# dp_source_model: IP-XACT component
VLNV IcronTechnologies:IcronTechnologies:dp_source_model:1.0

## Parameters
addr_width = 9
bus_width = 32

## Bus interfaces (logical=physical port)
default_map: slave AGNISYS:AGNISYS:APB:1.0, memory map dp_sourcemap
  pclk=pclk, presetn=presetn, psel=psel, penable=penable, pwrite=pwrite, pprot=pprot, pstrb=pstrb, pwdata=pwdata, paddr=paddr, pready=pready, prdata=prdata, pslverr=pslverr

## Ports
in pclk
in presetn
in psel
in penable
in pwrite
in pprot[2:0]
in pstrb[(bus_width div 8 )-1:0]
in pwdata[bus_width -1:0]
in paddr[addr_width -1:0]
out pready
out prdata[bus_width -1:0]
out pslverr
out dp_source_regsversion_major_r[7:0]
out dp_source_regsversion_minor_r[7:0]
out dp_source_regsversion_patch_r[7:0]
out dp_source_regsconfiguration_enb
out dp_source_regsconfiguration_debug_sel_r[3:0]
out dp_source_regsconfiguration_dp_training_done_r
out dp_source_regsconfiguration_vid_stream_end_r
out dp_source_regsconfiguration_apb_to_axi_mode_select_r
out dp_source_regsconfiguration_pix_gen_mode_r[1:0]
out dp_source_regsconfiguration_pix_gen_sel_r
out dp_source_regsconfiguration_dp_enh_frm_en_r
out dp_source_regsconfiguration_decoder_error_inject_r
out dp_source_regsconfiguration_vid_stream_generator_en_r
out dp_source_regsconfiguration_syn_stream_generator_en_r
out dp_source_regsconfiguration_sdp_en_r
out dp_source_regsconfiguration_lane_bit_rate_r[1:0]
out dp_source_regsconfiguration_tps_sel_r[3:0]
out dp_source_regsconfiguration_lane_num_r[1:0]
out dp_source_regsscrambler_enb
out dp_source_regsscrambler_enable_r
out dp_source_regsstream_generator_cfg{n}_enb (n=0..3)
out dp_source_regsstream_generator_cfg0_cs_start_level_r[11:0]
out dp_source_regsstream_generator_cfg0_cs_pkt_length_r[9:0]
out dp_source_regsstream_generator_cfg0_pix_start_level_r[9:0]
out dp_source_regsstream_generator_cfg1_cs_fifo_level_check_frequency_r[9:0]
out dp_source_regsstream_generator_cfg1_cs_pkt_interval_r[12:0]
out dp_source_regsstream_generator_cfg2_cs_pkt_interval_feedback_ctrl_r
out dp_source_regsstream_generator_cfg2_cs_pkt_interval_feedback_ctrl_debug_r[3:0]
out dp_source_regsstream_generator_cfg2_cs_pkt_interval_minus_offset0_r[3:0]
out dp_source_regsstream_generator_cfg2_cs_pkt_interval_plus_offset0_r[3:0]
out dp_source_regsstream_generator_cfg3_dp_width_total_feedback_ctrl_r
out dp_source_regsstream_generator_cfg3_dp_width_total_feedback_ctrl_debug_r[3:0]
out dp_source_regsstream_generator_cfg3_dp_width_total_minus_offset1_r[3:0]
out dp_source_regsstream_generator_cfg3_dp_width_total_plus_offset1_r[3:0]
out dp_source_regsstream_generator_cfg3_dp_width_total_minus_offset0_r[3:0]
out dp_source_regsstream_generator_cfg3_dp_width_total_plus_offset0_r[3:0]
out dp_source_regsstream_generator_alu{n}_enb (n=0..2)
out dp_source_regsstream_generator_alu0_dp_width_active_r[14:0]
out dp_source_regsstream_generator_alu0_dp_width_total_r[14:0]
out dp_source_regsstream_generator_alu1_full_tu_size_r[6:0]
out dp_source_regsstream_generator_alu1_last_tu_size_r[6:0]
out dp_source_regsstream_generator_alu1_full_tu_num_r[8:0]
out dp_source_regsstream_generator_alu2_cpu_math_result_rdy_r
out dp_source_regsstream_generator_alu2_valid_bytes_repeat_num_r[8:0]
out dp_source_regsstream_generator_alu2_valid_bytes_per_full_tu_r[6:0]
out dp_source_regsstream_generator_alu2_valid_bytes_num_per_lane_r[14:0]
out dp_source_regsstream_generator_fifo_cs_control0_enb
out dp_source_regsstream_generator_fifo_cs_control0_aet0_r[15:0]
out dp_source_regsstream_generator_fifo_cs_control0_aft0_r[15:0]
out dp_source_regsstream_generator_fifo_cs_control1_enb
out dp_source_regsstream_generator_fifo_cs_control1_aet1_r[15:0]
out dp_source_regsstream_generator_fifo_cs_control1_aft1_r[15:0]
out dp_source_regsstream_generator_fifo_pix_control{n}_enb (n=0..2)
out dp_source_regsstream_generator_fifo_pix_control0_aet0_r[15:0]
out dp_source_regsstream_generator_fifo_pix_control0_aft0_r[15:0]
out dp_source_regsstream_generator_fifo_pix_control1_aet1_r[15:0]
out dp_source_regsstream_generator_fifo_pix_control1_aft1_r[15:0]
out dp_source_regsstream_generator_fifo_pix_control2_offset_r[15:0]
out dp_source_regsstream_generator_sdp_ctrl_enb
out dp_source_regsstream_generator_sdp_ctrl_maud_set_value_r[7:0]
out dp_source_regsstream_generator_sdp_ctrl_maud_method_sel_r
out dp_source_regsstream_generator_sdp_ctrl_audiomute_flag_r
out dp_source_regsstream_generator_idle_pattern_debug_enb
out dp_source_regsstream_generator_idle_pattern_debug_cnt_rst_r
out dp_source_regsstream_generator_msa_control_0_enb
out dp_source_regsstream_generator_msa_control_0_nvid_sel_r
out dp_source_regsstream_generator_msa_control_0_mvid_sel_r[1:0]
out dp_source_regsstream_generator_msa_control_0_mvid_set_value_r[23:0]
out dp_source_regsstream_generator_msa_control_1_enb
out dp_source_regsstream_generator_msa_control_1_insert_line_sel_r[7:0]
out dp_source_regsstream_generator_msa_control_1_nvid_set_value_r[23:0]
out dp_source_regsstream_generator_msa_mvid_enb
out dp_source_regsstream_generator_msa_mvid_mvid_r[23:0]
out dp_source_regsstream_generator_msa_nvid_enb
out dp_source_regsstream_generator_msa_nvid_nvid_r[23:0]
out dp_source_regsstream_generator_msa_horizontal_0_enb
out dp_source_regsstream_generator_msa_horizontal_0_total_r[15:0]
out dp_source_regsstream_generator_msa_horizontal_0_start_r[15:0]
out dp_source_regsstream_generator_msa_horizontal_1_enb
out dp_source_regsstream_generator_msa_horizontal_1_width_r[15:0]
out dp_source_regsstream_generator_msa_horizontal_1_polarity_r
out dp_source_regsstream_generator_msa_horizontal_1_sync_width_r[14:0]
out dp_source_regsstream_generator_msa_vertical_0_enb
out dp_source_regsstream_generator_msa_vertical_0_total_r[15:0]
out dp_source_regsstream_generator_msa_vertical_0_start_r[15:0]
out dp_source_regsstream_generator_msa_vertical_1_enb
out dp_source_regsstream_generator_msa_vertical_1_height_r[15:0]
out dp_source_regsstream_generator_msa_vertical_1_polarity_r
out dp_source_regsstream_generator_msa_vertical_1_sync_width_r[14:0]
out dp_source_regsstream_generator_msa_misc_enb
out dp_source_regsstream_generator_msa_misc_reserved_r[2:0]
out dp_source_regsstream_generator_msa_misc_vsc_sdp_r
out dp_source_regsstream_generator_msa_misc_y_only_r
out dp_source_regsstream_generator_msa_misc_stereo_r[1:0]
out dp_source_regsstream_generator_msa_misc_int_total_r
out dp_source_regsstream_generator_msa_misc_color_r[6:0]
out dp_source_regsstream_generator_msa_misc_clk_sync_r
out dp_source_regscompliance_custom_80bits_3_0_enb
out dp_source_regscompliance_custom_80bits_3_0_byte{n}_r[7:0] (n=0..3)
out dp_source_regscompliance_custom_80bits_7_4_enb
out dp_source_regscompliance_custom_80bits_7_4_byte{n}_r[7:0] (n=4..7)
out dp_source_regscompliance_custom_80bits_9_8_enb
out dp_source_regscompliance_custom_80bits_9_8_byte9_r[7:0]
out dp_source_regscompliance_custom_80bits_9_8_byte8_r[7:0]
out dp_source_regsstats0_rd2clr_config_rd_valid_out
out dp_source_regsstats0_rd2clr_config_wr_valid_out
out dp_source_regsstats0_fifo_pix_0_full_rd_valid_out
out dp_source_regsstats0_fifo_pix_0_empty_rd_valid_out
out dp_source_regsstats0_fifo_pix_0_overflow_rd_valid_out
out dp_source_regsstats0_fifo_pix_0_underflow_rd_valid_out
out dp_source_regsstats0_pix_{n}_sr_underflow_rd_valid_out (n=0..3)
out dp_source_regsstats0_fifo_pix_0_level_rd_valid_out
out dp_source_regsstats0_fifo_pix_0_level_watermark_rd_valid_out
out dp_source_regsstats1_rd2clr_config_rd_valid_out
out dp_source_regsstats1_rd2clr_config_wr_valid_out
out dp_source_regsstats1_fifo_cs_full_rd_valid_out
out dp_source_regsstats1_fifo_cs_empty_rd_valid_out
out dp_source_regsstats1_fifo_cs_overflow_rd_valid_out
out dp_source_regsstats1_fifo_cs_underflow_rd_valid_out
out dp_source_regsstats1_fifo_cs_ae0_rd_valid_out
out dp_source_regsstats1_fifo_cs_ae1_rd_valid_out
out dp_source_regsstats1_fifo_cs_af0_rd_valid_out
out dp_source_regsstats1_fifo_cs_af1_rd_valid_out
out dp_source_regsstats1_fifo_cs_level_rd_valid_out
out dp_source_regsstats1_fifo_cs_level_watermark_rd_valid_out
out dp_source_regsstats1_fifo_sdp_full_rd_valid_out
out dp_source_regsstats1_fifo_sdp_empty_rd_valid_out
out dp_source_regsstats1_fifo_sdp_overflow_rd_valid_out
out dp_source_regsstats1_fifo_sdp_underflow_rd_valid_out
out dp_source_regsstats1_fifo_sdp_level_rd_valid_out
out dp_source_regsstats1_fifo_sdp_level_watermark_rd_valid_out
out dp_source_regsstats1_fifo_sdp_tag_full_rd_valid_out
out dp_source_regsstats1_fifo_sdp_tag_empty_rd_valid_out
out dp_source_regsstats1_fifo_sdp_tag_overflow_rd_valid_out
out dp_source_regsstats1_fifo_sdp_tag_underflow_rd_valid_out
out dp_source_regsstats1_fifo_sdp_tag_level_rd_valid_out
out dp_source_regsstats1_fifo_sdp_tag_level_watermark_rd_valid_out
out dp_source_regsstats1_sdp_ptp_pkt_sop_in_rd_valid_out

## Address spaces and blocks
dp_sourcemap.dp_source: base 0x000, range 0x200, width 32

## Registers
Registers are 32-bit, read-only, reset 0x0 unless marked. A register's access mark holds for its fields unless they carry their own. Offsets are from the block's base; lines under a group give offsets from that group; [hi:lo] are bit positions; {n}, {i} and the like mark numbered series; 'fields as' and 'values as' point back to an identical list; <NAME> marks a mode.

## dp_sourcemap.dp_source — DP Source
Base 0x00000000
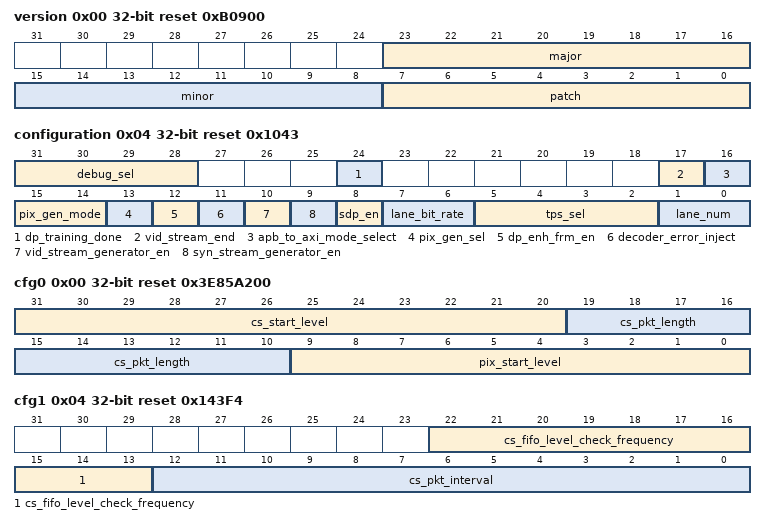
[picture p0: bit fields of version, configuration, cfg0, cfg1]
0x00 version reset 0xB0900
  [23:16] major — Major version
  [15:8] minor — Minor version
  [7:0] patch — Patch version
0x04 configuration rw reset 0x1043 — General configuration
  [31:28] debug_sel — Misc debug bits
  [24] dp_training_done — DP training is completed
  [17] vid_stream_end — The video stream is ended
  [16] apb_to_axi_mode_select — APB to AXI read mode select 1'b1: The read cycle is at least one clock later than read address cycle 1'b0: The read cycle happens at the same cycle as read address cycle
  [15:14] pix_gen_mode — Pixel generator mode select 2'b00: black 2'b01: white 2'b10: Gray 2'b11: dark gray
  [13] pix_gen_sel — Select pixel generator as input to stream generator 0: Input from IntoPix decoder 1:Input from pixel generator
  [12] dp_enh_frm_en — DP enhanced framing mode enable. The enhanced mode is enabled when this bit is set to 1.
  [11] decoder_error_inject — Write 1 to inject a cycle of random error.
  [10] vid_stream_generator_en — Enable video related logic in stream_generator module
  [9] syn_stream_generator_en — Enable DP stream synthesize related logic in stream_generator module
  [8] sdp_en — SDP enable. The SDP function is enabled when it is 1
  [7:6] lane_bit_rate — DP serial bit rate 2'b00: RBR (1.62 Gbps) 2'b01: HBR (2.70 Gbps) 2'b10: HBR2 (5.40 Gbps) 2'b11: HBR3(8.10 Gbps)
  [5:2] tps_sel — Training pattern selection 4'd0: TPS0 (No test pattern. DP functional mode 4'd1: TPS1 4'd2: TPS2 4'd3: TPS3 4'd4: CP2520 pattern 1 4'd5: CP2520 pattern 2- 4'd6: CP2520 pattern 2+ 4'd7: CP2520 pattern 3 (Also called TPS4) 4'd8: Custom 80-bit pattern
  [1:0] lane_num — Number of active dp lanes 2'b00: 1 lane 2'b01: 2 lanes 2'b10: Invalid 2'b11: 4 lanes
0x08 scrambler rw
  [0] enable — Scrambler enable bit. The scrambler is enabled when this bit is set to 1. The scrambler is bypassed when this bit is set to 0
0x0C stream_generator group
  0x00 cfg0 rw reset 0x3E85A200
    [31:20] cs_start_level — The level cs buffer needs to filled before is read
    [19:10] cs_pkt_length — The length of code stream packet
    [9:0] pix_start_level — The level elasticity buffer needs to filled before is read
  0x04 cfg1 rw reset 0x143F4
    [22:13] cs_fifo_level_check_frequency — The frequency of allowing CS packet interval to be updated. The unit is number of lines. It is applicable if "cs_pkt_interval_feedback_ctrl_debug" is set to 1 otherwise the update occurs at every line.
    [12:0] cs_pkt_interval — The average interval of cs packets
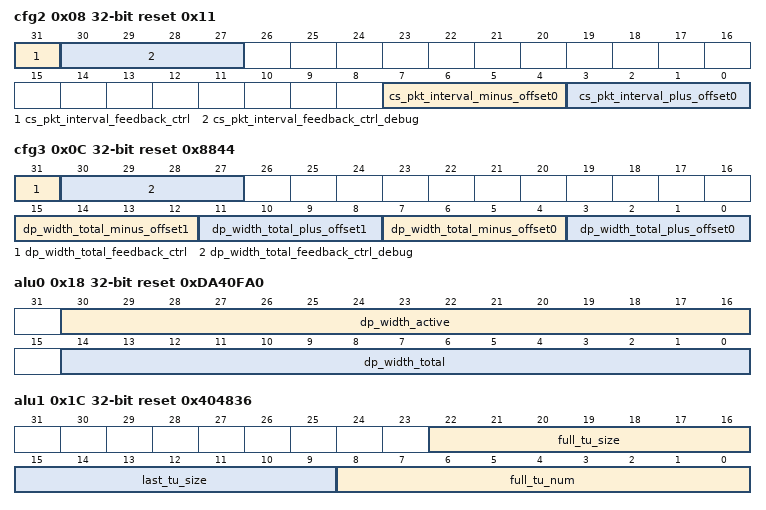
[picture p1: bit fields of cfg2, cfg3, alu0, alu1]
  0x08 cfg2 rw reset 0x11
    [31] cs_pkt_interval_feedback_ctrl — CS packet interval feedback control 1'b0: Use cs_pkt_interval register as input to negative feedback logic 1'b1: Use previous latched value as input to negative feedback logic
    [30:27] cs_pkt_interval_feedback_ctrl_debug — CS packet interval feedback control debug bits
    [7:4] cs_pkt_interval_minus_offset0 — CS packet interval minus offset 0
    [3:0] cs_pkt_interval_plus_offset0 — CS packet interval plus offset 0
  0x0C cfg3 rw reset 0x8844
    [31] dp_width_total_feedback_ctrl — DP width feedback control 1'b0: Use dp_width_total register as input to negative feedback logic 1'b1: Use previous latched value as input to negative feedback logic
    [30:27] dp_width_total_feedback_ctrl_debug — DP width feedback control debug bits
    [15:12] dp_width_total_minus_offset1 — DP total width minus offset 1 used when read and write rates are within the
    [11:8] dp_width_total_plus_offset1 — DP total width plus offset 1
    [7:4] dp_width_total_minus_offset0 — DP total width minus offset 0
    [3:0] dp_width_total_plus_offset0 — DP total width plus offset 0
  0x10 cs_pkt_updated_interval
    [12:0] debug — CS packet updated interval
  0x14 dp_width_total_actual
    [14:0] debug — DP actual total width
  0x18 alu0 rw reset 0xDA40FA0
    [30:16] dp_width_active — Active region DP width per lane in symbol
    [14:0] dp_width_total — Total DP width per lane in symbol
  0x1C alu1 rw reset 0x404836
    [22:16] full_tu_size
    [15:9] last_tu_size
    [8:0] full_tu_num — Number of full TU units
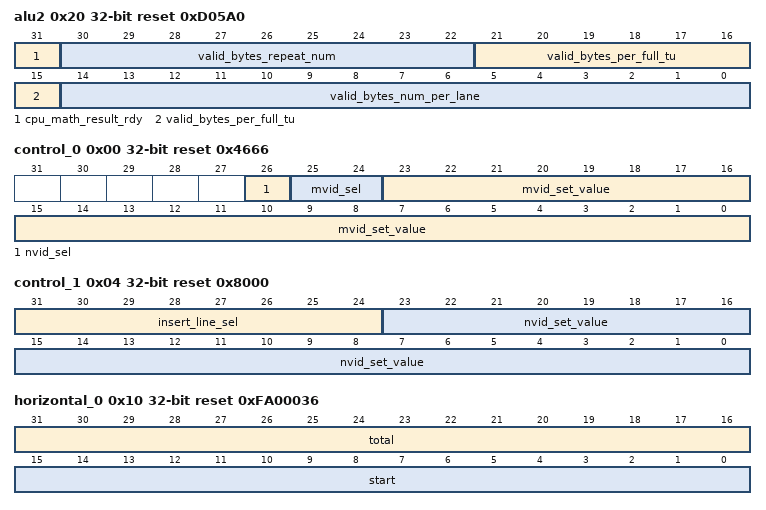
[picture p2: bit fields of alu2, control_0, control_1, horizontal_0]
  0x20 alu2 rw reset 0xD05A0
    [31] cpu_math_result_rdy — CPU calculation results are ready
    [30:22] valid_bytes_repeat_num — Number of TUs with valid bytes per full TU before increment by one
    [21:15] valid_bytes_per_full_tu — Number of valid bytes in one transfer unit per lane
    [14:0] valid_bytes_num_per_lane — Number of valid bytes per lane per line
  0x24 msa group
    0x00 control_0 rw reset 0x4666
      [26] nvid_sel — DP stream NVID sel 1: Use nvid_set_value register 0: Use nvid in the MSA packet sent by LEX
      [25:24] mvid_sel — DP stream MVID sel 2'b00: : Use measured value with mvid in the MSA packet sent by LEX for the initial value 2'b01: Use mvid_set_value register 2'b10: Use measured value with mvid_set_value register for the initial value. 2'b11: use mvid in the MSA packet sent by LEX
      [23:0] mvid_set_value — mvid set value when msa_mvid_sel is 2'b01
    0x04 control_1 rw reset 0x8000
      [31:24] insert_line_sel — Vertical blanking line selection for MSA insertion
      [23:0] nvid_set_value — nvid set value when msa_nvid_sel is 1'b0
    0x08 mvid rw
      [23:0] mvid — msa mvid value
    0x0C nvid rw
      [23:0] nvid — msa nvid value
    0x10 horizontal_0 rw reset 0xFA00036
      [31:16] total — msa h total
      [15:0] start — msa h start
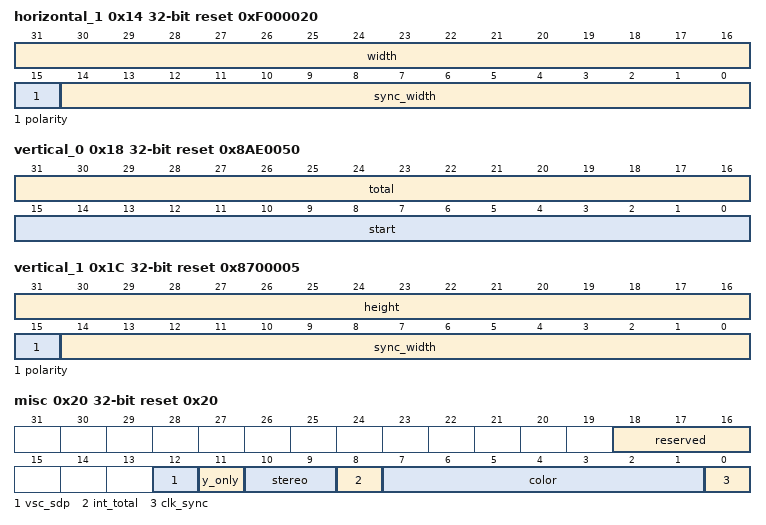
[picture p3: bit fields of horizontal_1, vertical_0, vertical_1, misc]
    0x14 horizontal_1 rw reset 0xF000020
      [31:16] width — msa h width
      [15] polarity — msa h sync polarity (hsp)
      [14:0] sync_width — msa h sync width (hsw)
    0x18 vertical_0 rw reset 0x8AE0050
      [31:16] total — msa v total
      [15:0] start — msa v start
    0x1C vertical_1 rw reset 0x8700005
      [31:16] height — msa v height
      [15] polarity — msa v sync polarity (vsp)
      [14:0] sync_width — msa v sync width (vsw)
    0x20 misc rw reset 0x20
      [18:16] reserved — msa misc_1 bits 5:3 field for reseved bits
      [12] vsc_sdp — msa misc_1 bit 6 field
      [11] y_only — msa misc_1 bit 7 field for Y-only and Raw video
      [10:9] stereo — msa misc_1 bits 2:1 field for Stereo video attribute 0 = No 3D video
      [8] int_total — msa misc_1 bit 0 field for interlaced video
      [7:1] color — msa misc_0 bits 7:1 for the Colorimetry field See DP 1.2 page 78 0x00 = RGB 18bpp 0x10 = RGB 24bpp 0x20 = RGB 30bpp 0x30 = RGB 36bpp 0x40 = RGB 48bpp
      [0] clk_sync — msa misc_0 bit 0 for synchronous clock. 0 = Link and main video clock are asynchronous 1 = Link and main video clock are synchronous
  0x48 msa_dp group
    0x00 mvid
      [23:0] mvid — Msa MVID value plugged into DP stream
    0x04 nvid
      [23:0] nvid — Msa NVID value plugged into DP stream
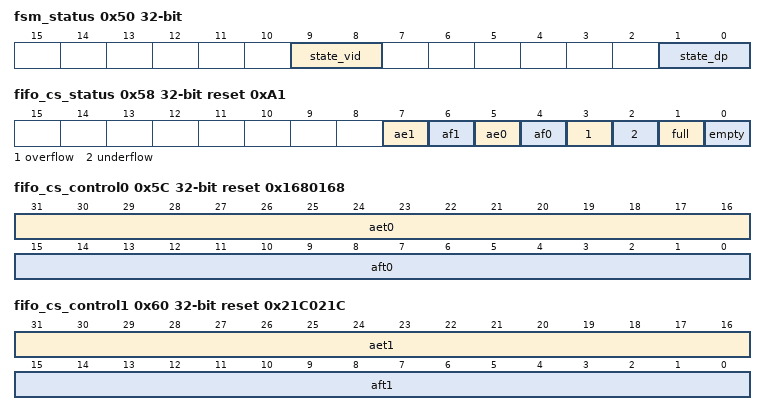
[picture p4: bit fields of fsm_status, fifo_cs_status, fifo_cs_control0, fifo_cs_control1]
  0x50 fsm_status — Stream generator module cs FIFO status register
    [9:8] state_vid — state_vid 00: e_idle 01: e_vs 10: e_dummy 11: N/A
    [1:0] state_dp — state_dp 00: e_wait 01: e_idle_pattern 10: e_video 11: N/A
  0x54 fifo_cs_level
    [15:0] level — Raw FIFO level
  0x58 fifo_cs_status reset 0xA1 — Stream generator module cs FIFO status register
    [7] ae1 — FIFO almost empty 1 status. A "1" indicates an almost empty or empty FIFO. The threshold level is set by aet1 field.
    [6] af1 — FIFO almost full 1 status. A "1" indicates an almost full or full FIFO. The threshold level is set by aft1 field.
    [5] ae0 — FIFO almost empty 0 status. A "1" indicates an almost empty or empty FIFO. The threshold level is set by aet0 field.
    [4] af0 — FIFO almost full 0 status. A "1" indicates an almost full or full FIFO. The threshold level is set by aft0 field.
    [3] overflow — FIFO overflow status. A "1" indicates overflow in FIFO.
    [2] underflow — FIFO underflow status. A "1" indicates underflow in FIFO.
    [1] full — FIFO full status. A "1" indicates FIFO is full
    [0] empty — FIFO empty status. A "1" indicates FIFO is empty
  0x5C fifo_cs_control0 rw reset 0x1680168 — FIFO threshold level controls set0
    [31:16] aet0 — FIFO almost empty 0 threshold setting. If FIFO level is equal or below this threshold then ae0 goes high
    [15:0] aft0 — FIFO almost full 0 threshold setting. If FIFO level is equal or above this threshold then af0 goes high
  0x60 fifo_cs_control1 rw reset 0x21C021C — FIFO threshold level controls set 1
    [31:16] aet1 — FIFO almost empty 1 threshold setting. If FIFO level is equal or below this threshold then ae1 goes high
    [15:0] aft1 — FIFO almost full 1 threshold setting. If FIFO level is equal or above this threshold then af1 goes high
  0x64 fifo_cs_config
    [15:0] depth — FIFO depth. This value is used for the build
  0x68 fifo_pix_level
    [15:0] level — Raw FIFO level
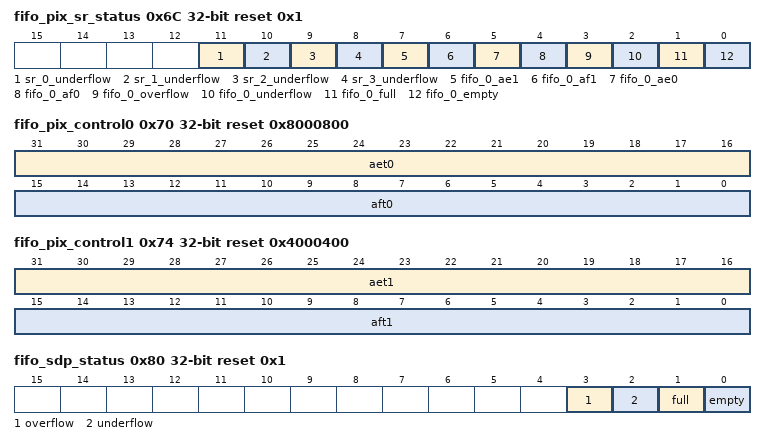
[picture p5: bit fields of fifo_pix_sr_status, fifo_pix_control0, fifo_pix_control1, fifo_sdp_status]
  0x6C fifo_pix_sr_status reset 0x1 — Packetizer module FIFO status register
    [11-n] sr_{n}_underflow (n=0..3) — SR {n} underflow status. A "1" indicates underflow in SR.
    [7] fifo_0_ae1 — FIFO almost empty 1 status. A "1" indicates an almost empty or empty FIFO. The threshold level is set by aet1 field.
    [6] fifo_0_af1 — FIFO almost full 1 status. A "1" indicates an almost full or full FIFO. The threshold level is set by aft1 field.
    [5] fifo_0_ae0 — FIFO almost empty 1 status. A "1" indicates an almost empty or empty FIFO. The threshold level is set by aet0 field.
    [4] fifo_0_af0 — FIFO almost full 1 status. A "1" indicates an almost full or full FIFO. The threshold level is set by aft0 field.
    [3] fifo_0_overflow — FIFO 0 overflow status. A "1" indicates overflow in FIFO.
    [2] fifo_0_underflow — FIFO 0 underflow status. A "1" indicates underflow in FIFO.
    [1] fifo_0_full — FIFO 0 full status. A "1" indicates FIFO is full
    [0] fifo_0_empty — FIFO 0 empty status. A "1" indicates FIFO is empty
  0x70 fifo_pix_control0 rw reset 0x8000800 — FIFO threshold level controls set0
    fields as stream_generator.fifo_cs_control0
  0x74 fifo_pix_control1 rw reset 0x4000400 — FIFO threshold level controls set 1
    fields as stream_generator.fifo_cs_control1
  0x78 fifo_pix_control2 rw — FIFO threshold level controls set 2
    [15:0] offset — The offset used to shift the threshold levels
  0x7C fifo_pix_config
    [15:0] depth — FIFO depth. This value is used for the build
  0x80 fifo_sdp_status reset 0x1 — SDP FIFO status register
    [3] overflow — FIFO overflow status. A "1" indicates overflow in FIFO.
    [2] underflow — FIFO underflow status. A "1" indicates underflow in FIFO.
    [1] full — FIFO full status. A "1" indicates FIFO is full
    [0] empty — FIFO empty status. A "1" indicates FIFO is empty
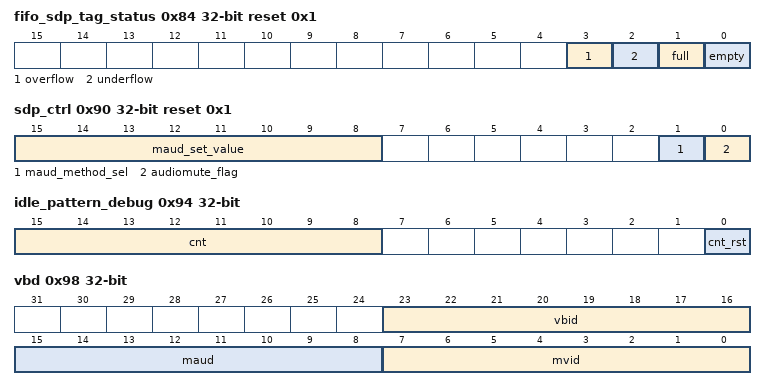
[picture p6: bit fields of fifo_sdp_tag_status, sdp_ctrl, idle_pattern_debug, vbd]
  0x84 fifo_sdp_tag_status reset 0x1 — SDP tag FIFO status register
    fields as stream_generator.fifo_sdp_status
  0x88 fifo_sdp_config
    [10:0] depth — FIFO depth. This value is used for the build
  0x8C fifo_sdp_tag_config
    [8:0] depth — FIFO depth. This value is used for the build
  0x90 sdp_ctrl rw reset 0x1
    [15:8] maud_set_value — The manual value used for Maud
    [1] maud_method_sel — The maud setting method 0: Manual value 1: Extracted value from audio time stamp packet
    [0] audiomute_flag — The audiomute flag received from LEX
  0x94 idle_pattern_debug access per field — Debug
    [15:8] cnt ro — Idle pattern count
    [0] cnt_rst rw — Idle pattern count reset
  0x98 vbd
    [23:16] vbid — vbid value
    [15:8] maud — maud value
    [7:0] mvid — Lower 8 bits of mvid[31:0]
0xA8 decoder_error_status group
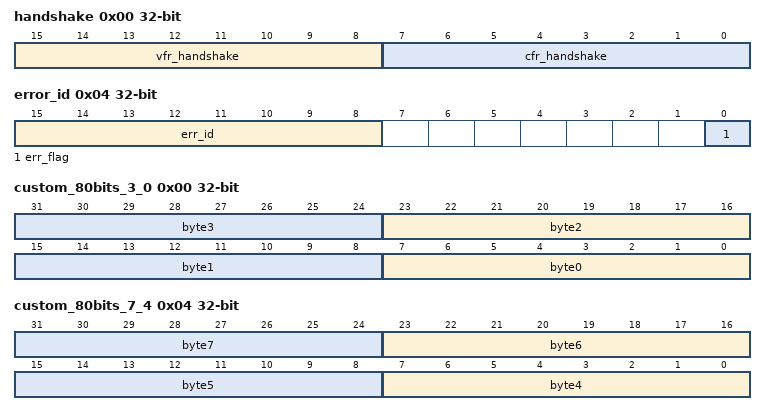
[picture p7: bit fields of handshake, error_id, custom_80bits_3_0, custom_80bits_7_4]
  0x00 handshake
    [15:8] vfr_handshake — Number of images with a fault on handshake (vid_enbl='1' while vid_valid='0')
    [7:0] cfr_handshake — Number of images with a fault on handshake (cs_enbl='1' while cs_ready='0')
  0x04 error_id
    [15:8] err_id — Error Identification when err_flag is set First error identified in the current frame: 1-2 = internal error 3 = error on the codestream input interface 4 = error on the video output interface 5 = mismatch between codestream header config and video size config 6 = external abort
    [0] err_flag — Error detected during the processing of the current frame.
0xB0 compliance group — Compliance 80bit custom patten
  0x00 custom_80bits_3_0 rw — Bytes 0 to 3
    [8n+7:8n] byte{n} (n=0..3) — TEST_80BIT_CUSTOM_PATTERN Value {8n+7}:{8n}
  0x04 custom_80bits_7_4 rw — Bytes 4 to 7
    [8n-25:8n-32] byte{n} (n=4..7) — TEST_80BIT_CUSTOM_PATTERN Value {8n+7}:{8n}
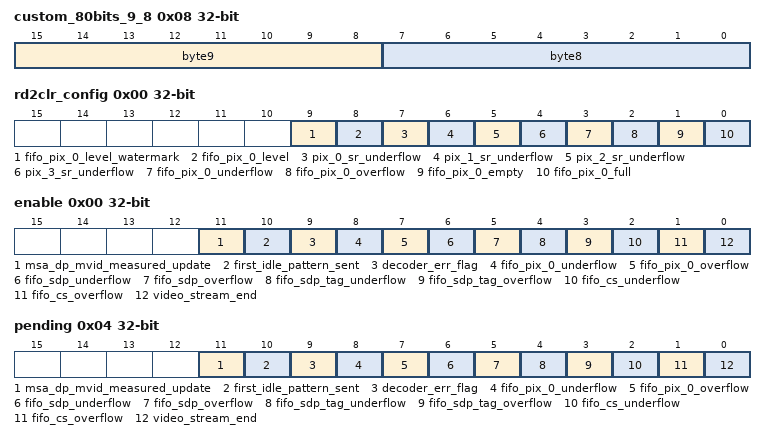
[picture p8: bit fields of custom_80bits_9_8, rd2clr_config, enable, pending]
  0x08 custom_80bits_9_8 rw — Bytes 9 to 10
    [15:8] byte9 — TEST_80BIT_CUSTOM_PATTERN Value 79:72
    [7:0] byte8 — TEST_80BIT_CUSTOM_PATTERN Value 71:64
0xBC stats0 group — All the Statistic Registers and their configuration.
  0x00 rd2clr_config rw — Configures if the stats register read by s/w clears the read register. A 1 in any bit configures the h/w to clear the corresponding stats register after a s/w read of that stats register.
    [9] fifo_pix_0_level_watermark, [8] fifo_pix_0_level, [7-n] pix_{n}_sr_underflow (n=0..3), [3] fifo_pix_0_underflow, [2] fifo_pix_0_overflow, [1] fifo_pix_0_empty, [0] fifo_pix_0_full
  0x04 fifo_pix_0_full — Pixel 0 FIFO full count
    [7:0] fifo_pix_0_full — _icron_event_detect_rising_edge_
  0x08 fifo_pix_0_empty — Pixel 0 FIFO empty count
    [7:0] fifo_pix_0_empty — _icron_event_detect_rising_edge_
  0x0C fifo_pix_0_overflow — Pixel 0 FIFO overflow count
    [7:0] fifo_pix_0_overflow
  0x10 fifo_pix_0_underflow — Pixel 0 FIFO underflow count
    [7:0] fifo_pix_0_underflow
  {0x14+4j} pix_{j}_sr_underflow (j=0..3) — Pixel {j} shift register underflow count
    [7:0] pix_{j}_sr_underflow
  0x24 fifo_pix_0_level — Pixel 0 FIFO level at beginning of DP frame
    [15:0] fifo_pix_0_level — _icron_no_counter_
  0x28 fifo_pix_0_level_watermark — Pixel 0 FIFO level at beginning of DP frame (watermark)
    [15:0] fifo_pix_0_level_watermark — _icron_no_counter_;_icron_water_marker_
0xE8 stats1 group — All the Statistic Registers and their configuration.
  0x00 rd2clr_config rw — Configures if the stats register read by s/w clears the read register. A 1 in any bit configures the h/w to clear the corresponding stats register after a s/w read of that stats register.
    [22] sdp_ptp_pkt_sop_in, [21] fifo_sdp_tag_level_watermark, [20] fifo_sdp_tag_level, [19] fifo_sdp_tag_underflow, [18] fifo_sdp_tag_overflow, [17] fifo_sdp_tag_empty, [16] fifo_sdp_tag_full, [15] fifo_sdp_level_watermark, [14] fifo_sdp_level, [13] fifo_sdp_underflow, [12] fifo_sdp_overflow, [11] fifo_sdp_empty, [10] fifo_sdp_full, [9] fifo_cs_level_watermark, [8] fifo_cs_level, [7] fifo_cs_af1, [6] fifo_cs_af0, [5] fifo_cs_ae1, [4] fifo_cs_ae0, [3] fifo_cs_underflow, [2] fifo_cs_overflow, [1] fifo_cs_empty, [0] fifo_cs_full
  0x04 fifo_cs_full — CS FIFO full count
    [7:0] fifo_cs_full — _icron_event_detect_rising_edge_
  0x08 fifo_cs_empty — CS FIFO empty count
    [7:0] fifo_cs_empty — _icron_event_detect_rising_edge_
  0x0C fifo_cs_overflow — CS FIFO overflow count
    [7:0] fifo_cs_overflow
  0x10 fifo_cs_underflow — CS FIFO underflow count
    [7:0] fifo_cs_underflow
  0x14 fifo_cs_ae0 — CS FIFO almost empty threshold 0 count
    [7:0] fifo_cs_ae0 — _icron_event_detect_rising_edge_
  0x18 fifo_cs_ae1 — CS FIFO almost empty threshold 1 count
    [7:0] fifo_cs_ae1 — _icron_event_detect_rising_edge_
  0x1C fifo_cs_af0 — CS FIFO almost full threshold 0 count
    [7:0] fifo_cs_af0 — _icron_event_detect_rising_edge_
  0x20 fifo_cs_af1 — CS FIFO almost full threshold 1 count
    [7:0] fifo_cs_af1 — _icron_event_detect_rising_edge_
  0x24 fifo_cs_level — CS FIFO level at beginning of DP frame
    [15:0] fifo_cs_level — _icron_no_counter_
  0x28 fifo_cs_level_watermark — CS FIFO level at beginning of DP frame (watermark)
    [15:0] fifo_cs_level_watermark — _icron_no_counter_;_icron_water_marker_
  0x2C fifo_sdp_full — SDP FIFO full count
    [7:0] fifo_sdp_full — _icron_event_detect_rising_edge_
  0x30 fifo_sdp_empty — SDP FIFO empty count
    [7:0] fifo_sdp_empty — _icron_event_detect_rising_edge_
  0x34 fifo_sdp_overflow — SDP FIFO overflow count
    [7:0] fifo_sdp_overflow
  0x38 fifo_sdp_underflow — SDP FIFO underflow count
    [7:0] fifo_sdp_underflow
  0x3C fifo_sdp_level — SDP FIFO level
    [15:0] fifo_sdp_level — _icron_no_counter_
  0x40 fifo_sdp_level_watermark — SDP FIFO level (watermark)
    [15:0] fifo_sdp_level_watermark — _icron_no_counter_;_icron_water_marker_
  0x44 fifo_sdp_tag_full — SDP tag FIFO full count
    [7:0] fifo_sdp_tag_full — _icron_event_detect_rising_edge_
  0x48 fifo_sdp_tag_empty — SDP tag FIFO empty count
    [7:0] fifo_sdp_tag_empty — _icron_event_detect_rising_edge_
  0x4C fifo_sdp_tag_overflow — SDP tag FIFO overflow count
    [7:0] fifo_sdp_tag_overflow
  0x50 fifo_sdp_tag_underflow — SDP tag FIFO underflow count
    [7:0] fifo_sdp_tag_underflow
  0x54 fifo_sdp_tag_level — SDP tag FIFO level
    [7:0] fifo_sdp_tag_level — _icron_no_counter_
  0x58 fifo_sdp_tag_level_watermark — SDP tag FIFO level (watermark)
    [7:0] fifo_sdp_tag_level_watermark — _icron_no_counter_;_icron_water_marker_
  0x5C sdp_ptp_pkt_sop_in — SDP PTP packets received
    [7:0] sdp_ptp_pkt_sop_in — _icron_event_detect_rising_edge_
0x148 irq group — source Interrupt register group
  0x00 enable rw — Interrupt Enable register - Write 1 to enable, 0 to mask an interrupt
    [11] msa_dp_mvid_measured_update — Set high to enable msa_dp_mvid_measured_update
    [10] first_idle_pattern_sent — Set high to enable first_idle_pattern_sent
    [9] decoder_err_flag — Set high to enable decoder_err_flag
    [8] fifo_pix_0_underflow — Set high to enable fifo_pix_0_underflow
    [7] fifo_pix_0_overflow — Set high to enable fifo_pix_0_overflow
    [6] fifo_sdp_underflow — Set high to enable fifo_sdp_underflow
    [5] fifo_sdp_overflow — Set high to enable fifo_sdp_overflow
    [4] fifo_sdp_tag_underflow — Set high to enable fifo_sdp_tag_underflow
    [3] fifo_sdp_tag_overflow — Set high to enable fifo_sdp_tag_overflow
    [2] fifo_cs_underflow — Set high to enable fifo_cs_underflow
    [1] fifo_cs_overflow — Set high to enable fifo_cs_overflow
    [0] video_stream_end — Set high to enable video_stream_end
  0x04 pending rw — Interrupt Pending register - This indicates which enabled interrupts have triggered, Write 1 to clear
    [11] msa_dp_mvid_measured_update write-1-clears — Registered msa_dp_mvid_measured_update
    [10] first_idle_pattern_sent write-1-clears — Registered first_idle_pattern_sent
    [9] decoder_err_flag write-1-clears — Registered decoder_err_flag
    [8] fifo_pix_0_underflow write-1-clears — Registered fifo_pix_0_underflow
    [7] fifo_pix_0_overflow write-1-clears — Registered fifo_pix_0_overflow
    [6] fifo_sdp_underflow write-1-clears — Registered fifo_sdp_underflow
    [5] fifo_sdp_overflow write-1-clears — Registered fifo_sdp_overflow
    [4] fifo_sdp_tag_underflow write-1-clears — Registered fifo_sdp_tag_underflow
    [3] fifo_sdp_tag_overflow write-1-clears — Registered fifo_sdp_tag_overflow
    [2] fifo_cs_underflow write-1-clears — Registered fifo_cs_underflow
    [1] fifo_cs_overflow write-1-clears — Registered fifo_cs_overflow
    [0] video_stream_end write-1-clears — Registered interrupt0
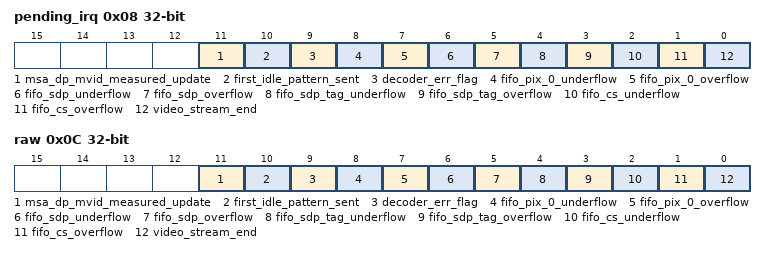
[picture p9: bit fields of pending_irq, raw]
  0x08 pending_irq — Interrupt Pending register - This indicates which enabled interrupts have triggered, Write 1 to clear
    [11] msa_dp_mvid_measured_update — Registered msa_dp_mvid_measured_update
    [10] first_idle_pattern_sent — Registered first_idle_pattern_sent
    [9] decoder_err_flag — Registered decoder_err_flag
    [8] fifo_pix_0_underflow — Registered fifo_pix_0_underflow
    [7] fifo_pix_0_overflow — Registered fifo_pix_0_overflow
    [6] fifo_sdp_underflow — Registered fifo_sdp_underflow
    [5] fifo_sdp_overflow — Registered fifo_sdp_overflow
    [4] fifo_sdp_tag_underflow — Registered fifo_sdp_tag_underflow
    [3] fifo_sdp_tag_overflow — Registered fifo_sdp_tag_overflow
    [2] fifo_cs_underflow — Registered fifo_cs_underflow
    [1] fifo_cs_overflow — Registered fifo_cs_overflow
    [0] video_stream_end — Registered interrupt0
  0x0C raw — This register contains the registered state of interrupt signals
    [11] msa_dp_mvid_measured_update — Current status of msa_dp_mvid_measured_update
    [10] first_idle_pattern_sent — Current status of first_idle_pattern_sent
    [9] decoder_err_flag — Current status of decoder_err_flag
    [8] fifo_pix_0_underflow — Current status of fifo_pix_0_underflow
    [7] fifo_pix_0_overflow — Current status of fifo_pix_0_overflow
    [6] fifo_sdp_underflow — Current status of fifo_sdp_underflow
    [5] fifo_sdp_overflow — Current status of fifo_sdp_overflow
    [4] fifo_sdp_tag_underflow — Current status of fifo_sdp_tag_underflow
    [3] fifo_sdp_tag_overflow — Current status of fifo_sdp_overflow
    [2] fifo_cs_underflow — Current status of fifo_cs_underflow
    [1] fifo_cs_overflow — Current status of fifo_cs_overflow
    [0] video_stream_end — Current status of interrupt0
